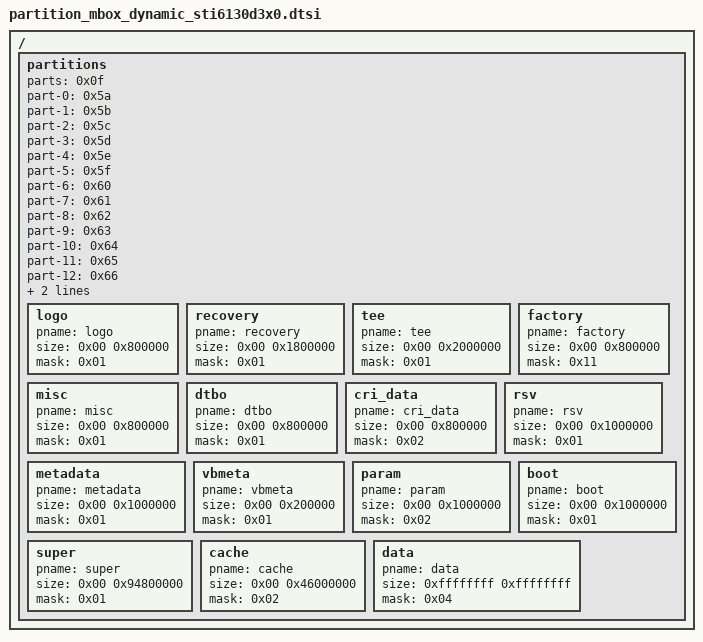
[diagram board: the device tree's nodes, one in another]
/*
 * Amlogic partition set for normal
 *
 * Copyright (c) 2017-2017 Amlogic Ltd
 *
 * This file is licensed under a dual GPLv2 or BSD license.
 *
 */

#include "firmware_avb_deadpool.dtsi"

/ {
	partitions {
		parts = <0x0f>;
		part-0 = <0x5a>;
		part-1 = <0x5b>;
		part-2 = <0x5c>;
		part-3 = <0x5d>;
		part-4 = <0x5e>;
		part-5 = <0x5f>;
		part-6 = <0x60>;
		part-7 = <0x61>;
		part-8 = <0x62>;
		part-9 = <0x63>;
		part-10 = <0x64>;
		part-11 = <0x65>;
		part-12 = <0x66>;
		part-13 = <0x67>;
		part-14 = <0x68>;
		phandle = <0x107>;

		logo {
			pname = "logo";
			size = <0x00 0x800000>;
			mask = <0x01>;
			phandle = <0x5a>;
		};

		recovery {
			pname = "recovery";
			size = <0x00 0x1800000>;
			mask = <0x01>;
			phandle = <0x5b>;
		};

		tee {
			pname = "tee";
			size = <0x00 0x2000000>;
			mask = <0x01>;
			phandle = <0x64>;
		};

		factory {
			pname = "factory";
			size = <0x00 0x800000>;
			mask = <0x11>;
			phandle = <0x65>;
		};

		misc {
			pname = "misc";
			size = <0x00 0x800000>;
			mask = <0x01>;
			phandle = <0x5c>;
		};

		dtbo {
			pname = "dtbo";
			size = <0x00 0x800000>;
			mask = <0x01>;
			phandle = <0x5d>;
		};

		cri_data {
			pname = "cri_data";
			size = <0x00 0x800000>;
			mask = <0x02>;
			phandle = <0x5e>;
		};

		rsv {
			pname = "rsv";
			size = <0x00 0x1000000>;
			mask = <0x01>;
			phandle = <0x61>;
		};

		metadata {
			pname = "metadata";
			size = <0x00 0x1000000>;
			mask = <0x01>;
			phandle = <0x62>;
		};

		vbmeta {
			pname = "vbmeta";
			size = <0x00 0x200000>;
			mask = <0x01>;
			phandle = <0x63>;
		};

		param {
			pname = "param";
			size = <0x00 0x1000000>;
			mask = <0x02>;
			phandle = <0x5f>;
		};

		boot {
			pname = "boot";
			size = <0x00 0x1000000>;
			mask = <0x01>;
			phandle = <0x60>;
		};

		super {
			pname = "super";
			size = <0x00 0x94800000>;
			mask = <0x01>;
			phandle = <0x66>;
		};

		cache {
			pname = "cache";
			size = <0x00 0x46000000>;
			mask = <0x02>;
			phandle = <0x67>;
		};

		data {
			pname = "data";
			size = <0xffffffff 0xffffffff>;
			mask = <0x04>;
			phandle = <0x68>;
		};
	};
};/* end of / */
